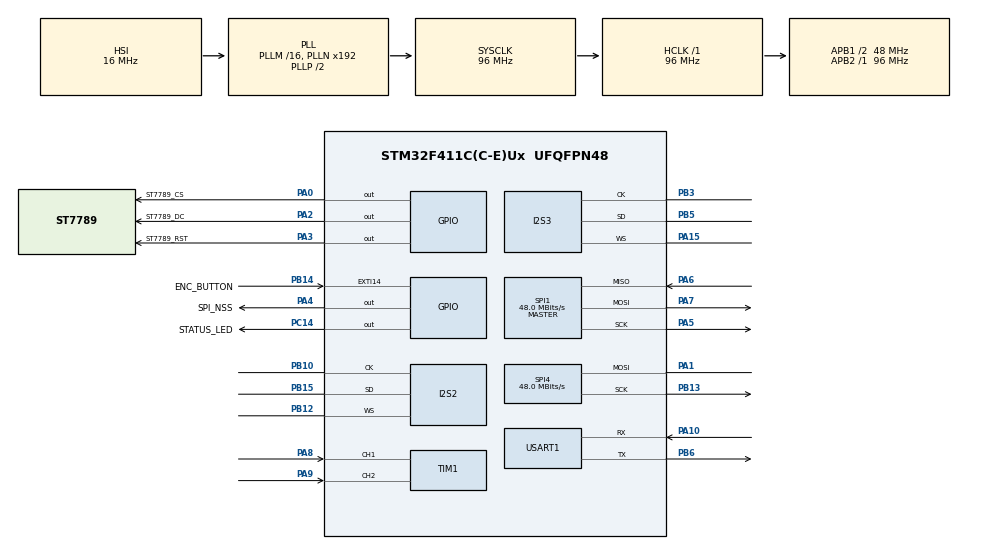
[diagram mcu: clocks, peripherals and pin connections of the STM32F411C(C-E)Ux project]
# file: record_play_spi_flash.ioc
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Dma.Request0=SPI2_RX
Dma.Request1=SPI3_TX
Dma.Request2=SPI4_TX
Dma.SPI2_RX.0.Direction=DMA_PERIPH_TO_MEMORY
Dma.SPI2_RX.0.FIFOMode=DMA_FIFOMODE_DISABLE
Dma.SPI2_RX.0.Instance=DMA1_Stream3
Dma.SPI2_RX.0.MemDataAlignment=DMA_MDATAALIGN_HALFWORD
Dma.SPI2_RX.0.MemInc=DMA_MINC_ENABLE
Dma.SPI2_RX.0.Mode=DMA_CIRCULAR
Dma.SPI2_RX.0.PeriphDataAlignment=DMA_PDATAALIGN_HALFWORD
Dma.SPI2_RX.0.PeriphInc=DMA_PINC_DISABLE
Dma.SPI2_RX.0.Priority=DMA_PRIORITY_VERY_HIGH
Dma.SPI3_TX.1.Direction=DMA_MEMORY_TO_PERIPH
Dma.SPI3_TX.1.FIFOMode=DMA_FIFOMODE_DISABLE
Dma.SPI3_TX.1.Instance=DMA1_Stream5
Dma.SPI3_TX.1.MemDataAlignment=DMA_MDATAALIGN_HALFWORD
Dma.SPI3_TX.1.MemInc=DMA_MINC_ENABLE
Dma.SPI3_TX.1.Mode=DMA_CIRCULAR
Dma.SPI3_TX.1.PeriphDataAlignment=DMA_PDATAALIGN_HALFWORD
Dma.SPI3_TX.1.PeriphInc=DMA_PINC_DISABLE
Dma.SPI3_TX.1.Priority=DMA_PRIORITY_HIGH
Dma.SPI4_TX.2.Direction=DMA_MEMORY_TO_PERIPH
Dma.SPI4_TX.2.FIFOMode=DMA_FIFOMODE_DISABLE
Dma.SPI4_TX.2.Instance=DMA2_Stream1
Dma.SPI4_TX.2.MemDataAlignment=DMA_MDATAALIGN_BYTE
Dma.SPI4_TX.2.MemInc=DMA_MINC_ENABLE
Dma.SPI4_TX.2.Mode=DMA_NORMAL
Dma.SPI4_TX.2.PeriphDataAlignment=DMA_PDATAALIGN_BYTE
Dma.SPI4_TX.2.PeriphInc=DMA_PINC_DISABLE
Dma.SPI4_TX.2.Priority=DMA_PRIORITY_LOW
I2S2.AudioFreq=I2S_AUDIOFREQ_16K
I2S2.DataFormat=I2S_DATAFORMAT_24B
I2S2.ErrorAudioFreq=-0.26 %
I2S2.FullDuplexMode=I2S_FULLDUPLEXMODE_DISABLE
I2S2.Instance=SPI$Index
I2S2.Mode=I2S_MODE_MASTER_RX
I2S2.RealAudioFreq=15.957 KHz
I2S2.VirtualMode=I2S_MODE_MASTER
I2S3.AudioFreq=I2S_AUDIOFREQ_16K
I2S3.DataFormat=I2S_DATAFORMAT_16B
I2S3.ErrorAudioFreq=-0.26 %
I2S3.FullDuplexMode=I2S_FULLDUPLEXMODE_DISABLE
I2S3.Instance=SPI$Index
I2S3.RealAudioFreq=15.957 KHz
I2S3.VirtualMode=I2S_MODE_MASTER
Mcu.Family=STM32F4
Mcu.Name=STM32F411C(C-E)Ux
Mcu.Package=UFQFPN48
NVIC.DMA1_Stream3_IRQn=true\:0\:0\:false\:false\:true\:false\:true\:true
NVIC.DMA1_Stream5_IRQn=true\:0\:0\:false\:false\:true\:false\:true\:true
NVIC.DMA2_Stream1_IRQn=true\:0\:0\:false\:false\:true\:false\:true\:true
NVIC.EXTI15_10_IRQn=true\:0\:0\:false\:false\:true\:true\:true\:true
NVIC.PriorityGroup=NVIC_PRIORITYGROUP_4
NVIC.TIM1_CC_IRQn=true\:0\:0\:false\:false\:true\:true\:true\:true
NVIC.TIM2_IRQn=true\:0\:0\:false\:false\:true\:true\:true\:true
NVIC.TIM3_IRQn=true\:0\:0\:false\:false\:true\:true\:true\:true
NVIC.USART1_IRQn=true\:0\:0\:false\:false\:true\:true\:true\:true
PA0-WKUP.GPIO_Label=ST7789_CS
PA0-WKUP.GPIO_Speed=GPIO_SPEED_FREQ_HIGH
PA0-WKUP.Signal=GPIO_Output
PA1.Mode=Simplex_Bidirectional_Master
PA1.Signal=SPI4_MOSI
PA10.Mode=Asynchronous
PA10.Signal=USART1_RX
PA13.Mode=Serial_Wire
PA13.Signal=SYS_JTMS-SWDIO
PA14.Mode=Serial_Wire
PA14.Signal=SYS_JTCK-SWCLK
PA15.Mode=Half_Duplex_Master
PA15.Signal=I2S3_WS
PA2.GPIO_Label=ST7789_DC
PA2.GPIO_Speed=GPIO_SPEED_FREQ_HIGH
PA2.Signal=GPIO_Output
PA3.GPIO_Label=ST7789_RST
PA3.GPIO_Speed=GPIO_SPEED_FREQ_MEDIUM
PA3.Signal=GPIO_Output
PA4.GPIO_Label=SPI_NSS
PA4.GPIO_Speed=GPIO_SPEED_FREQ_VERY_HIGH
PA4.PinState=GPIO_PIN_SET
PA4.Signal=GPIO_Output
PA5.Mode=Full_Duplex_Master
PA5.Signal=SPI1_SCK
PA6.Mode=Full_Duplex_Master
PA6.Signal=SPI1_MISO
PA7.Mode=Full_Duplex_Master
PA7.Signal=SPI1_MOSI
PA8.GPIO_PuPd=GPIO_PULLUP
PA8.Signal=S_TIM1_CH1
PA9.GPIO_PuPd=GPIO_PULLUP
PA9.Signal=S_TIM1_CH2
PB10.Mode=Half_Duplex_Master
PB10.Signal=I2S2_CK
PB12.Mode=Half_Duplex_Master
PB12.Signal=I2S2_WS
PB13.Mode=Simplex_Bidirectional_Master
PB13.Signal=SPI4_SCK
PB14.GPIO_Label=ENC_BUTTON
PB14.GPIO_ModeDefaultEXTI=GPIO_MODE_IT_RISING_FALLING
PB14.GPIO_PuPd=GPIO_PULLUP
PB14.Signal=GPXTI14
PB15.Mode=Half_Duplex_Master
PB15.Signal=I2S2_SD
PB3.Mode=Half_Duplex_Master
PB3.Signal=I2S3_CK
PB5.Mode=Half_Duplex_Master
PB5.Signal=I2S3_SD
PB6.Mode=Asynchronous
PB6.Signal=USART1_TX
PC14-OSC32_IN.GPIO_Label=STATUS_LED
PC14-OSC32_IN.Signal=GPIO_Output
ProjectManager.HeapSize=0x200
ProjectManager.StackSize=0x400
ProjectManager.TargetToolchain=STM32CubeIDE
RCC.AHBFreq_Value=96000000
RCC.APB1CLKDivider=RCC_HCLK_DIV2
RCC.APB1Freq_Value=48000000
RCC.APB1TimFreq_Value=96000000
RCC.APB2Freq_Value=96000000
RCC.APB2TimFreq_Value=96000000
RCC.CortexFreq_Value=96000000
RCC.HCLKFreq_Value=96000000
RCC.HSE_VALUE=25000000
RCC.HSI_VALUE=16000000
RCC.LSE_VALUE=32768
RCC.SYSCLKFreq_VALUE=96000000
RCC.SYSCLKSource=RCC_SYSCLKSOURCE_PLLCLK
RCC.VCOOutputFreq_Value=192000000
SH.S_TIM1_CH1.0=TIM1_CH1,Encoder_Interface
SH.S_TIM1_CH2.0=TIM1_CH2,Encoder_Interface
SPI1.BaudRatePrescaler=SPI_BAUDRATEPRESCALER_2
SPI1.CalculateBaudRate=48.0 MBits/s
SPI1.Direction=SPI_DIRECTION_2LINES
SPI1.Mode=SPI_MODE_MASTER
SPI1.VirtualType=VM_MASTER
SPI4.CalculateBaudRate=48.0 MBits/s
SPI4.Direction=SPI_DIRECTION_1LINE
SPI4.Mode=SPI_MODE_MASTER
SPI4.VirtualType=VM_MASTER
TIM1.EncoderMode=TIM_ENCODERMODE_TI12
TIM1.IC1Filter=15
TIM1.IC1Polarity=TIM_ICPOLARITY_FALLING
TIM1.IC2Filter=15
TIM1.IC2Polarity=TIM_ICPOLARITY_FALLING
TIM2.AutoReloadPreload=TIM_AUTORELOAD_PRELOAD_DISABLE
TIM2.Period=245
TIM2.Prescaler=65535
TIM3.Period=15
TIM3.Prescaler=65535
USART1.VirtualMode=VM_ASYNC
VP_TIM2_VS_ClockSourceINT.Mode=Internal
VP_TIM3_VS_ClockSourceINT.Mode=Internal
board=custom

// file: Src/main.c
/* USER CODE BEGIN Header */
/**
  ******************************************************************************
  * @file           : main.c
  * @brief          : Main program body
  ******************************************************************************
  * @attention
  *
  * Copyright (c) 2023 STMicroelectronics.
  * All rights reserved.
  *
  * This software is licensed under terms that can be found in the LICENSE file
  * in the root directory of this software component.
  * If no LICENSE file comes with this software, it is provided AS-IS.
  *
  ******************************************************************************
  */

//  - Investigate improving LCD performance - increase buffer size?
//  - Change menu options when clip has been recorded
//    - display play and store options
//
/* USER CODE END Header */
#include "main.h"

/* USER CODE BEGIN Includes */
#include "application.h"
/* USER CODE END Includes */

I2S_HandleTypeDef hi2s2;
I2S_HandleTypeDef hi2s3;
DMA_HandleTypeDef hdma_spi2_rx;
DMA_HandleTypeDef hdma_spi3_tx;

SPI_HandleTypeDef hspi1;
SPI_HandleTypeDef hspi4;
DMA_HandleTypeDef hdma_spi4_tx;

TIM_HandleTypeDef htim1;
TIM_HandleTypeDef htim2;
TIM_HandleTypeDef htim3;

UART_HandleTypeDef huart1;

void SystemClock_Config(void);
void PeriphCommonClock_Config(void);
static void MX_GPIO_Init(void);
static void MX_DMA_Init(void);
static void MX_USART1_UART_Init(void);
static void MX_SPI1_Init(void);
static void MX_I2S2_Init(void);
static void MX_I2S3_Init(void);
static void MX_TIM2_Init(void);
static void MX_SPI4_Init(void);
static void MX_TIM1_Init(void);
static void MX_TIM3_Init(void);

int main(void)
{

  /* MCU Configuration--------------------------------------------------------*/

  /* Reset of all peripherals, Initializes the Flash interface and the Systick. */
  HAL_Init();

  /* Configure the system clock */
  SystemClock_Config();

/* Configure the peripherals common clocks */
  PeriphCommonClock_Config();

  /* Initialize all configured peripherals */
  MX_GPIO_Init();
  MX_DMA_Init();
  MX_USART1_UART_Init();
  MX_SPI1_Init();
  MX_I2S2_Init();
  MX_I2S3_Init();
  MX_TIM2_Init();
  MX_SPI4_Init();
  MX_TIM1_Init();
  MX_TIM3_Init();
  /* USER CODE BEGIN 2 */

  appInit(&hi2s2, &hi2s3, &hspi1, &htim2, &htim1, &htim3);
  appLoop();
  /* USER CODE END 2 */

  /* Infinite loop */
  while (1)
  {

  }
}

void SystemClock_Config(void)
{
  RCC_OscInitTypeDef RCC_OscInitStruct = {0};
  RCC_ClkInitTypeDef RCC_ClkInitStruct = {0};

  /** Configure the main internal regulator output voltage
  */
  __HAL_RCC_PWR_CLK_ENABLE();
  __HAL_PWR_VOLTAGESCALING_CONFIG(PWR_REGULATOR_VOLTAGE_SCALE1);

  /** Initializes the RCC Oscillators according to the specified parameters
  * in the RCC_OscInitTypeDef structure.
  */
  RCC_OscInitStruct.OscillatorType = RCC_OSCILLATORTYPE_HSI;
  RCC_OscInitStruct.HSIState = RCC_HSI_ON;
  RCC_OscInitStruct.HSICalibrationValue = RCC_HSICALIBRATION_DEFAULT;
  RCC_OscInitStruct.PLL.PLLState = RCC_PLL_ON;
  RCC_OscInitStruct.PLL.PLLSource = RCC_PLLSOURCE_HSI;
  RCC_OscInitStruct.PLL.PLLM = 16;
  RCC_OscInitStruct.PLL.PLLN = 192;
  RCC_OscInitStruct.PLL.PLLP = RCC_PLLP_DIV2;
  RCC_OscInitStruct.PLL.PLLQ = 4;
  if (HAL_RCC_OscConfig(&RCC_OscInitStruct) != HAL_OK)
  {
    Error_Handler();
  }

  /** Initializes the CPU, AHB and APB buses clocks
  */
  RCC_ClkInitStruct.ClockType = RCC_CLOCKTYPE_HCLK|RCC_CLOCKTYPE_SYSCLK
                              |RCC_CLOCKTYPE_PCLK1|RCC_CLOCKTYPE_PCLK2;
  RCC_ClkInitStruct.SYSCLKSource = RCC_SYSCLKSOURCE_PLLCLK;
  RCC_ClkInitStruct.AHBCLKDivider = RCC_SYSCLK_DIV1;
  RCC_ClkInitStruct.APB1CLKDivider = RCC_HCLK_DIV2;
  RCC_ClkInitStruct.APB2CLKDivider = RCC_HCLK_DIV1;

  if (HAL_RCC_ClockConfig(&RCC_ClkInitStruct, FLASH_LATENCY_3) != HAL_OK)
  {
    Error_Handler();
  }
}

void PeriphCommonClock_Config(void)
{
  RCC_PeriphCLKInitTypeDef PeriphClkInitStruct = {0};

  /** Initializes the peripherals clock
  */
  PeriphClkInitStruct.PeriphClockSelection = RCC_PERIPHCLK_I2S;
  PeriphClkInitStruct.PLLI2S.PLLI2SN = 192;
  PeriphClkInitStruct.PLLI2S.PLLI2SM = 16;
  PeriphClkInitStruct.PLLI2S.PLLI2SR = 2;
  if (HAL_RCCEx_PeriphCLKConfig(&PeriphClkInitStruct) != HAL_OK)
  {
    Error_Handler();
  }
}

static void MX_I2S2_Init(void)
{

  hi2s2.Instance = SPI2;
  hi2s2.Init.Mode = I2S_MODE_MASTER_RX;
  hi2s2.Init.Standard = I2S_STANDARD_PHILIPS;
  hi2s2.Init.DataFormat = I2S_DATAFORMAT_24B;
  hi2s2.Init.MCLKOutput = I2S_MCLKOUTPUT_DISABLE;
  hi2s2.Init.AudioFreq = I2S_AUDIOFREQ_16K;
  hi2s2.Init.CPOL = I2S_CPOL_LOW;
  hi2s2.Init.ClockSource = I2S_CLOCK_PLL;
  hi2s2.Init.FullDuplexMode = I2S_FULLDUPLEXMODE_DISABLE;
  if (HAL_I2S_Init(&hi2s2) != HAL_OK)
  {
    Error_Handler();
  }

}

static void MX_I2S3_Init(void)
{

  hi2s3.Instance = SPI3;
  hi2s3.Init.Mode = I2S_MODE_MASTER_TX;
  hi2s3.Init.Standard = I2S_STANDARD_PHILIPS;
  hi2s3.Init.DataFormat = I2S_DATAFORMAT_16B;
  hi2s3.Init.MCLKOutput = I2S_MCLKOUTPUT_DISABLE;
  hi2s3.Init.AudioFreq = I2S_AUDIOFREQ_16K;
  hi2s3.Init.CPOL = I2S_CPOL_LOW;
  hi2s3.Init.ClockSource = I2S_CLOCK_PLL;
  hi2s3.Init.FullDuplexMode = I2S_FULLDUPLEXMODE_DISABLE;
  if (HAL_I2S_Init(&hi2s3) != HAL_OK)
  {
    Error_Handler();
  }

}

static void MX_SPI1_Init(void)
{

  /* SPI1 parameter configuration*/
  hspi1.Instance = SPI1;
  hspi1.Init.Mode = SPI_MODE_MASTER;
  hspi1.Init.Direction = SPI_DIRECTION_2LINES;
  hspi1.Init.DataSize = SPI_DATASIZE_8BIT;
  hspi1.Init.CLKPolarity = SPI_POLARITY_LOW;
  hspi1.Init.CLKPhase = SPI_PHASE_1EDGE;
  hspi1.Init.NSS = SPI_NSS_SOFT;
  hspi1.Init.BaudRatePrescaler = SPI_BAUDRATEPRESCALER_2;
  hspi1.Init.FirstBit = SPI_FIRSTBIT_MSB;
  hspi1.Init.TIMode = SPI_TIMODE_DISABLE;
  hspi1.Init.CRCCalculation = SPI_CRCCALCULATION_DISABLE;
  hspi1.Init.CRCPolynomial = 10;
  if (HAL_SPI_Init(&hspi1) != HAL_OK)
  {
    Error_Handler();
  }

}

static void MX_SPI4_Init(void)
{

  /* SPI4 parameter configuration*/
  hspi4.Instance = SPI4;
  hspi4.Init.Mode = SPI_MODE_MASTER;
  hspi4.Init.Direction = SPI_DIRECTION_1LINE;
  hspi4.Init.DataSize = SPI_DATASIZE_8BIT;
  hspi4.Init.CLKPolarity = SPI_POLARITY_LOW;
  hspi4.Init.CLKPhase = SPI_PHASE_1EDGE;
  hspi4.Init.NSS = SPI_NSS_SOFT;
  hspi4.Init.BaudRatePrescaler = SPI_BAUDRATEPRESCALER_2;
  hspi4.Init.FirstBit = SPI_FIRSTBIT_MSB;
  hspi4.Init.TIMode = SPI_TIMODE_DISABLE;
  hspi4.Init.CRCCalculation = SPI_CRCCALCULATION_DISABLE;
  hspi4.Init.CRCPolynomial = 10;
  if (HAL_SPI_Init(&hspi4) != HAL_OK)
  {
    Error_Handler();
  }

}

static void MX_TIM1_Init(void)
{

  TIM_Encoder_InitTypeDef sConfig = {0};
  TIM_MasterConfigTypeDef sMasterConfig = {0};

  htim1.Instance = TIM1;
  htim1.Init.Prescaler = 0;
  htim1.Init.CounterMode = TIM_COUNTERMODE_UP;
  htim1.Init.Period = 65535;
  htim1.Init.ClockDivision = TIM_CLOCKDIVISION_DIV1;
  htim1.Init.RepetitionCounter = 0;
  htim1.Init.AutoReloadPreload = TIM_AUTORELOAD_PRELOAD_DISABLE;
  sConfig.EncoderMode = TIM_ENCODERMODE_TI12;
  sConfig.IC1Polarity = TIM_ICPOLARITY_FALLING;
  sConfig.IC1Selection = TIM_ICSELECTION_DIRECTTI;
  sConfig.IC1Prescaler = TIM_ICPSC_DIV1;
  sConfig.IC1Filter = 15;
  sConfig.IC2Polarity = TIM_ICPOLARITY_FALLING;
  sConfig.IC2Selection = TIM_ICSELECTION_DIRECTTI;
  sConfig.IC2Prescaler = TIM_ICPSC_DIV1;
  sConfig.IC2Filter = 15;
  if (HAL_TIM_Encoder_Init(&htim1, &sConfig) != HAL_OK)
  {
    Error_Handler();
  }
  sMasterConfig.MasterOutputTrigger = TIM_TRGO_RESET;
  sMasterConfig.MasterSlaveMode = TIM_MASTERSLAVEMODE_DISABLE;
  if (HAL_TIMEx_MasterConfigSynchronization(&htim1, &sMasterConfig) != HAL_OK)
  {
    Error_Handler();
  }

}

static void MX_TIM2_Init(void)
{

  TIM_ClockConfigTypeDef sClockSourceConfig = {0};
  TIM_MasterConfigTypeDef sMasterConfig = {0};

  htim2.Instance = TIM2;
  htim2.Init.Prescaler = 65535;
  htim2.Init.CounterMode = TIM_COUNTERMODE_UP;
  htim2.Init.Period = 245;
  htim2.Init.ClockDivision = TIM_CLOCKDIVISION_DIV1;
  htim2.Init.AutoReloadPreload = TIM_AUTORELOAD_PRELOAD_DISABLE;
  if (HAL_TIM_Base_Init(&htim2) != HAL_OK)
  {
    Error_Handler();
  }
  sClockSourceConfig.ClockSource = TIM_CLOCKSOURCE_INTERNAL;
  if (HAL_TIM_ConfigClockSource(&htim2, &sClockSourceConfig) != HAL_OK)
  {
    Error_Handler();
  }
  sMasterConfig.MasterOutputTrigger = TIM_TRGO_RESET;
  sMasterConfig.MasterSlaveMode = TIM_MASTERSLAVEMODE_DISABLE;
  if (HAL_TIMEx_MasterConfigSynchronization(&htim2, &sMasterConfig) != HAL_OK)
  {
    Error_Handler();
  }

}

static void MX_TIM3_Init(void)
{

  TIM_ClockConfigTypeDef sClockSourceConfig = {0};
  TIM_MasterConfigTypeDef sMasterConfig = {0};

  htim3.Instance = TIM3;
  htim3.Init.Prescaler = 65535;
  htim3.Init.CounterMode = TIM_COUNTERMODE_UP;
  htim3.Init.Period = 15;
  htim3.Init.ClockDivision = TIM_CLOCKDIVISION_DIV1;
  htim3.Init.AutoReloadPreload = TIM_AUTORELOAD_PRELOAD_DISABLE;
  if (HAL_TIM_Base_Init(&htim3) != HAL_OK)
  {
    Error_Handler();
  }
  sClockSourceConfig.ClockSource = TIM_CLOCKSOURCE_INTERNAL;
  if (HAL_TIM_ConfigClockSource(&htim3, &sClockSourceConfig) != HAL_OK)
  {
    Error_Handler();
  }
  sMasterConfig.MasterOutputTrigger = TIM_TRGO_RESET;
  sMasterConfig.MasterSlaveMode = TIM_MASTERSLAVEMODE_DISABLE;
  if (HAL_TIMEx_MasterConfigSynchronization(&htim3, &sMasterConfig) != HAL_OK)
  {
    Error_Handler();
  }

}

static void MX_USART1_UART_Init(void)
{

  huart1.Instance = USART1;
  huart1.Init.BaudRate = 115200;
  huart1.Init.WordLength = UART_WORDLENGTH_8B;
  huart1.Init.StopBits = UART_STOPBITS_1;
  huart1.Init.Parity = UART_PARITY_NONE;
  huart1.Init.Mode = UART_MODE_TX_RX;
  huart1.Init.HwFlowCtl = UART_HWCONTROL_NONE;
  huart1.Init.OverSampling = UART_OVERSAMPLING_16;
  if (HAL_UART_Init(&huart1) != HAL_OK)
  {
    Error_Handler();
  }

}

static void MX_DMA_Init(void)
{

  /* DMA controller clock enable */
  __HAL_RCC_DMA1_CLK_ENABLE();
  __HAL_RCC_DMA2_CLK_ENABLE();

  /* DMA interrupt init */
  /* DMA1_Stream3_IRQn interrupt configuration */
  HAL_NVIC_SetPriority(DMA1_Stream3_IRQn, 0, 0);
  HAL_NVIC_EnableIRQ(DMA1_Stream3_IRQn);
  /* DMA1_Stream5_IRQn interrupt configuration */
  HAL_NVIC_SetPriority(DMA1_Stream5_IRQn, 0, 0);
  HAL_NVIC_EnableIRQ(DMA1_Stream5_IRQn);
  /* DMA2_Stream1_IRQn interrupt configuration */
  HAL_NVIC_SetPriority(DMA2_Stream1_IRQn, 0, 0);
  HAL_NVIC_EnableIRQ(DMA2_Stream1_IRQn);

}

static void MX_GPIO_Init(void)
{
  GPIO_InitTypeDef GPIO_InitStruct = {0};

  /* GPIO Ports Clock Enable */
  __HAL_RCC_GPIOC_CLK_ENABLE();
  __HAL_RCC_GPIOA_CLK_ENABLE();
  __HAL_RCC_GPIOB_CLK_ENABLE();

  /*Configure GPIO pin Output Level */
  HAL_GPIO_WritePin(STATUS_LED_GPIO_Port, STATUS_LED_Pin, GPIO_PIN_RESET);

  /*Configure GPIO pin Output Level */
  HAL_GPIO_WritePin(GPIOA, ST7789_CS_Pin|ST7789_DC_Pin|ST7789_RST_Pin, GPIO_PIN_RESET);

  /*Configure GPIO pin Output Level */
  HAL_GPIO_WritePin(SPI_NSS_GPIO_Port, SPI_NSS_Pin, GPIO_PIN_SET);

  /*Configure GPIO pin : STATUS_LED_Pin */
  GPIO_InitStruct.Pin = STATUS_LED_Pin;
  GPIO_InitStruct.Mode = GPIO_MODE_OUTPUT_PP;
  GPIO_InitStruct.Pull = GPIO_NOPULL;
  GPIO_InitStruct.Speed = GPIO_SPEED_FREQ_LOW;
  HAL_GPIO_Init(STATUS_LED_GPIO_Port, &GPIO_InitStruct);

  /*Configure GPIO pins : ST7789_CS_Pin ST7789_DC_Pin */
  GPIO_InitStruct.Pin = ST7789_CS_Pin|ST7789_DC_Pin;
  GPIO_InitStruct.Mode = GPIO_MODE_OUTPUT_PP;
  GPIO_InitStruct.Pull = GPIO_NOPULL;
  GPIO_InitStruct.Speed = GPIO_SPEED_FREQ_HIGH;
  HAL_GPIO_Init(GPIOA, &GPIO_InitStruct);

  /*Configure GPIO pin : ST7789_RST_Pin */
  GPIO_InitStruct.Pin = ST7789_RST_Pin;
  GPIO_InitStruct.Mode = GPIO_MODE_OUTPUT_PP;
  GPIO_InitStruct.Pull = GPIO_NOPULL;
  GPIO_InitStruct.Speed = GPIO_SPEED_FREQ_MEDIUM;
  HAL_GPIO_Init(ST7789_RST_GPIO_Port, &GPIO_InitStruct);

  /*Configure GPIO pin : SPI_NSS_Pin */
  GPIO_InitStruct.Pin = SPI_NSS_Pin;
  GPIO_InitStruct.Mode = GPIO_MODE_OUTPUT_PP;
  GPIO_InitStruct.Pull = GPIO_NOPULL;
  GPIO_InitStruct.Speed = GPIO_SPEED_FREQ_VERY_HIGH;
  HAL_GPIO_Init(SPI_NSS_GPIO_Port, &GPIO_InitStruct);

  /*Configure GPIO pin : ENC_BUTTON_Pin */
  GPIO_InitStruct.Pin = ENC_BUTTON_Pin;
  GPIO_InitStruct.Mode = GPIO_MODE_IT_RISING_FALLING;
  GPIO_InitStruct.Pull = GPIO_PULLUP;
  HAL_GPIO_Init(ENC_BUTTON_GPIO_Port, &GPIO_InitStruct);

  /* EXTI interrupt init*/
  HAL_NVIC_SetPriority(EXTI15_10_IRQn, 0, 0);
  HAL_NVIC_EnableIRQ(EXTI15_10_IRQn);

}

void Error_Handler(void)
{
  __disable_irq();
  while (1)
  {
  }
}
